CM_ "IMPORT _stellantis_common_ram_hd_generated.dbc";

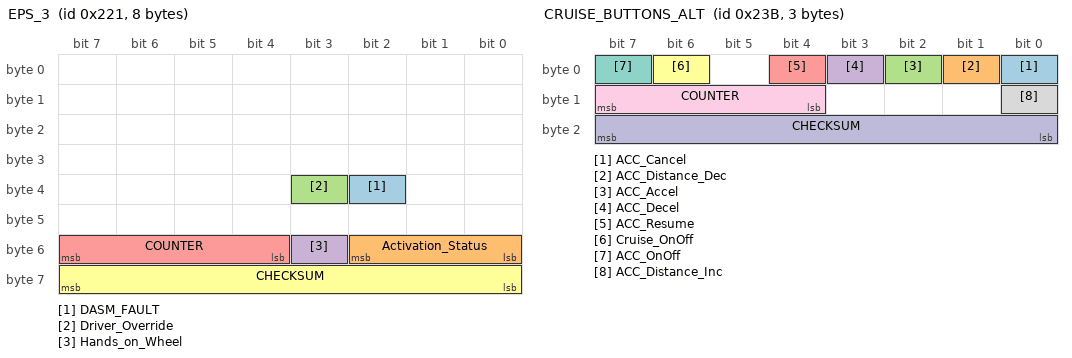
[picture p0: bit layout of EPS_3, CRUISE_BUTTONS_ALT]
BO_ 545 EPS_3: 8 XXX
 SG_ DASM_FAULT : 34|1@0+ (1,0) [0|1] "" XXX
 SG_ Activation_Status : 48|3@1+ (1,0) [0|1] "" XXX
 SG_ Driver_Override : 35|1@0+ (1,0) [0|1] "" XXX
 SG_ Hands_on_Wheel : 51|1@0+ (1,0) [0|1] "" XXX
 SG_ COUNTER : 55|4@0+ (1,0) [0|15] "" XXX
 SG_ CHECKSUM : 63|8@0+ (1,0) [0|255] "" XXX

BO_ 571 CRUISE_BUTTONS_ALT: 3 XXX
 SG_ ACC_Cancel : 0|1@1+ (1,0) [0|0] "" XXX
 SG_ ACC_Distance_Dec : 1|1@1+ (1,0) [0|0] "" XXX
 SG_ ACC_Accel : 2|1@1+ (1,0) [0|0] "" XXX
 SG_ ACC_Decel : 3|1@1+ (1,0) [0|0] "" XXX
 SG_ ACC_Resume : 4|1@0+ (1,0) [0|1] "" XXX
 SG_ Cruise_OnOff : 6|1@1+ (1,0) [0|0] "" XXX
 SG_ ACC_OnOff : 7|1@1+ (1,0) [0|0] "" XXX
 SG_ ACC_Distance_Inc : 8|1@1+ (1,0) [0|0] "" XXX
 SG_ COUNTER : 15|4@0+ (1,0) [0|15] "" XXX
 SG_ CHECKSUM : 23|8@0+ (1,0) [0|255] "" XXX

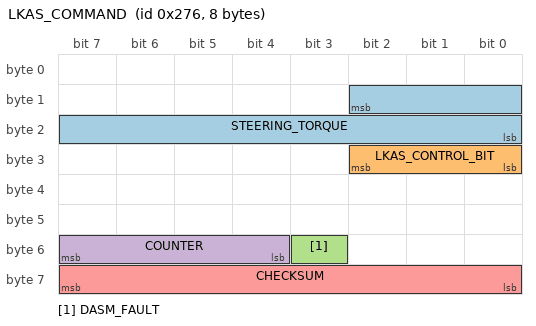
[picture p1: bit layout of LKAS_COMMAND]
BO_ 630 LKAS_COMMAND: 8 XXX
 SG_ STEERING_TORQUE : 10|11@0+ (1,-1024) [0|1] "" XXX
 SG_ LKAS_CONTROL_BIT : 24|3@1+ (1,0) [0|1] "" XXX
 SG_ DASM_FAULT : 51|1@0+ (1,0) [0|1] "" XXX
 SG_ COUNTER : 55|4@0+ (1,0) [0|15] "" XXX
 SG_ CHECKSUM : 63|8@0+ (1,0) [0|255] "" XXX

BO_ 650 Center_Stack_2: 8 XXX
 SG_ LKAS_Button : 57|1@1+ (1,0) [0|0] "" XXX

BO_ 816 Center_Stack_1: 8 XXX
 SG_ LKAS_Button : 53|1@1+ (1,0) [0|0] "" XXX
 SG_ Traction_Button : 54|1@0+ (1,0) [0|1] "" XXX
